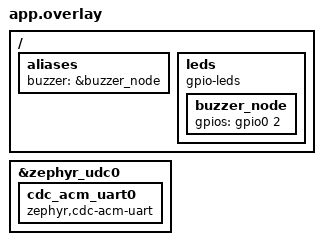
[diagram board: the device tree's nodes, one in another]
/* Device tree overlay: add CDC ACM UART to the nRF52840 */
&zephyr_udc0 {
    cdc_acm_uart0: cdc_acm_uart0 {
        compatible = "zephyr,cdc-acm-uart";
    };
};

/ {
    aliases {
        buzzer = &buzzer_node;
    };

    leds {
        compatible = "gpio-leds";
        buzzer_node: buzzer_node {
            gpios = <&gpio0 2 GPIO_ACTIVE_HIGH>; /* your piezo pin */
        };
    };
};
